AUTOSAR XML (schema 4-2-1)
# Copyright © Vector Informatik GmbH 2016
# License is invalid! Element <SLP> cannot be found.
# The created file must only be used with Vectors MICROSAR Basic Software. Please contact Vector Informatik to obtain a license.
standard types defined: boolean, sint8, uint8
package /VehicleProject
  system System
package /NM
  nm config NmConfig: can-nm-cluster-coupling=coupled-cluster=CAN00_CAN
    can nm cluster CAN00_CAN: communication-cluster=CAN00, nm-channel-id=0, nm-msg-cycle-time=0.1, nm-network-timeout=1, nm-repeat-message-time=0.4, nm-user-data-length=6, nm-wait-bus-sleep-time=0.75
      can nm node MyECU: controller=CT_CAN00, nm-if-ecu=MyECU_CAN, nm-node-id=0, rx-nm-pdu=msg_nm_RearECU_oCAN00, tx-nm-pdu=msg_nm_MyECU_oCAN00, nm-msg-cycle-offset=0, nm-msg-reduced-time=0.05, nm-range-config={lower-can-id=1024, upper-can-id=1087}
      can nm node RearECU: nm-if-ecu=RearECU_CAN, nm-node-id=1, rx-nm-pdu=msg_nm_MyECU_oCAN00, tx-nm-pdu=msg_nm_RearECU_oCAN00, nm-msg-cycle-offset=0, nm-msg-reduced-time=0.05, nm-range-config={lower-can-id=1024, upper-can-id=1087}
      can nm node Tester: nm-if-ecu=Tester_CAN, nm-node-id=0, nm-passive-mode-enabled=true, nm-msg-cycle-offset=0, nm-msg-reduced-time=0.05, nm-range-config={lower-can-id=1024, upper-can-id=1087}
    nm-if-ecus:
      nm ecu MyECU_CAN: ecu-instance=MyECU, nm-node-id-enabled=true, nm-user-data-enabled=true
      nm ecu RearECU_CAN: nm-node-id-enabled=true, nm-user-data-enabled=true
      nm ecu Tester_CAN: nm-node-id-enabled=true, nm-passive-mode-enabled=true, nm-user-data-enabled=true
package /TP
  can tp config CAN00_CAN: communication-cluster=CAN00, can-tp-ecu{cycle-time-main-function=0.005, ecu-instance=MyECU}
    can tp channel TPCH: channel-id=0, channel-mode=FULL-DUPLEX-MODE
    tp-connections:
      addressing-format=STANDARD, can-tp-channel=TPCH, data-pdu=msg_diag_RequestGlobal_Tp_oCAN00, receiver=TN_MyECU, ta-type=FUNCTIONAL, tp-sdu=msg_diag_RequestGlobal_oCAN00, transmitter=TN_Tester
      addressing-format=STANDARD, can-tp-channel=TPCH, data-pdu=msg_diag_Response_MyECU_Tp_oCAN00, flow-control-pdu=msg_diag_Request_MyECU_Tp_oCAN00, receiver=TN_Tester, ta-type=PHYSICAL, tp-sdu=msg_diag_Response_MyECU_oCAN00, transmitter=TN_MyECU
      addressing-format=STANDARD, can-tp-channel=TPCH, data-pdu=msg_diag_Request_MyECU_Tp_oCAN00, flow-control-pdu=msg_diag_Response_MyECU_Tp_oCAN00, receiver=TN_MyECU, ta-type=PHYSICAL, tp-sdu=msg_diag_Request_MyECU_oCAN00, transmitter=TN_Tester
    can tp node TN_MyECU: connector=CN_CAN00
    can tp node TN_Tester
package /Cluster
  can cluster CAN00: protocol-name=CAN
    can physical channel CHNL: comm-connectors=CN_CAN00
      frame msg_diag_Request_MyECU_oCAN00: id 0x610, to MyECU, frame-length=8, can-addressing-mode=STANDARD
        n pdu msg_diag_Request_MyECU_Tp_oCAN00: length=8
      frame msg_diag_RequestGlobal_oCAN00: id 0x614, to MyECU, frame-length=8, can-addressing-mode=STANDARD
        n pdu msg_diag_RequestGlobal_Tp_oCAN00: length=8
      frame msg_diag_Response_MyECU_oCAN00: id 0x612, from MyECU, frame-length=8, can-addressing-mode=STANDARD
        n pdu msg_diag_Response_MyECU_Tp_oCAN00: length=8
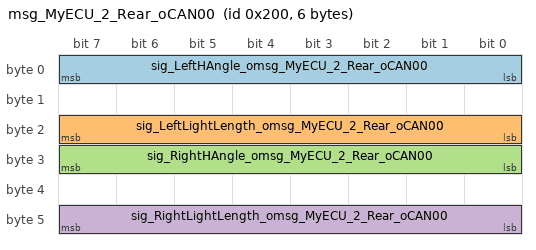
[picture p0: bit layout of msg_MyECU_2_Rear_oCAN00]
      frame msg_MyECU_2_Rear_oCAN00: id 0x200, from MyECU, frame-length=6, can-addressing-mode=STANDARD
        pdu msg_MyECU_2_Rear_oCAN00: length=6, minimum-delay=0, transmission-mode-false-timing=cyclic-timing={time-offset=0, time-period=0.1}, transmission-mode-true-timing=cyclic-timing={time-offset=0, time-period=0.1}, unused-bit-pattern=0
          signal sig_LeftHAngle_omsg_MyECU_2_Rear_oCAN00: start 0, 8 bit, little-endian, init-value=0, base-type=sint8, compu {phys=raw for raw -128..127}, transfer-property=PENDING
          signal sig_LeftLightLength_omsg_MyECU_2_Rear_oCAN00: start 16, 8 bit, little-endian, init-value=0, base-type=uint8, compu {phys=raw for raw 0..255}, transfer-property=PENDING
          signal sig_RightHAngle_omsg_MyECU_2_Rear_oCAN00: start 24, 8 bit, little-endian, init-value=0, base-type=sint8, compu {phys=raw for raw -128..127}, transfer-property=PENDING
          signal sig_RightLightLength_omsg_MyECU_2_Rear_oCAN00: start 40, 8 bit, little-endian, init-value=0, base-type=uint8, compu {phys=raw for raw 0..255}, transfer-property=PENDING
      frame msg_MyECU_2_Rear_Door_oCAN00: id 0x100, from MyECU, frame-length=8, can-addressing-mode=STANDARD
        pdu msg_MyECU_2_Rear_Door_oCAN00: length=8, minimum-delay=0, unused-bit-pattern=0
          signal sig_DoorLock_omsg_MyECU_2_Rear_Door_oCAN00: start 0, 8 bit, little-endian, init-value=0, base-type=sint8, compu {phys=raw for raw 0..1}, transfer-property=PENDING
      frame msg_nm_MyECU_oCAN00: id 0x400, from MyECU, frame-length=8, can-addressing-mode=STANDARD
        nm pdu msg_nm_MyECU_oCAN00: length=8, unused-bit-pattern=0
      frame msg_nm_RearECU_oCAN00: id 0x401, to MyECU, frame-length=8, can-addressing-mode=STANDARD
        nm pdu msg_nm_RearECU_oCAN00: length=8, unused-bit-pattern=0
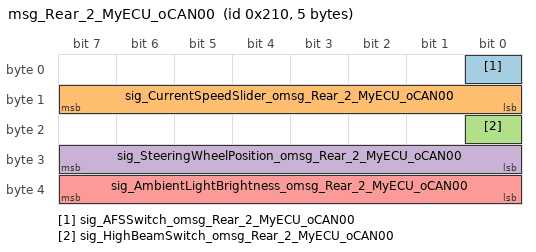
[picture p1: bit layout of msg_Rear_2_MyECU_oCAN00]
      frame msg_Rear_2_MyECU_oCAN00: id 0x210, to MyECU, frame-length=5, can-addressing-mode=STANDARD
        pdu msg_Rear_2_MyECU_oCAN00: length=5, minimum-delay=0, transmission-mode-false-timing=cyclic-timing={time-offset=0, time-period=0.1}, transmission-mode-true-timing=cyclic-timing={time-offset=0, time-period=0.1}, unused-bit-pattern=0
          signal sig_AFSSwitch_omsg_Rear_2_MyECU_oCAN00: start 0, 1 bit, little-endian, init-value=0, base-type=boolean, compu {phys=raw for raw 0..1}, transfer-property=PENDING, to MyECU
          signal sig_CurrentSpeedSlider_omsg_Rear_2_MyECU_oCAN00: start 8, 8 bit, little-endian, init-value=0, base-type=uint8, compu {phys=raw for raw 0..255}, transfer-property=PENDING, to MyECU
          signal sig_HighBeamSwitch_omsg_Rear_2_MyECU_oCAN00: start 16, 1 bit, little-endian, init-value=0, base-type=boolean, compu {phys=raw for raw 0..1}, transfer-property=PENDING, to MyECU
          signal sig_SteeringWheelPosition_omsg_Rear_2_MyECU_oCAN00: start 24, 8 bit, little-endian, init-value=0, base-type=sint8, compu {phys=raw for raw -128..127}, transfer-property=PENDING, to MyECU
          signal sig_AmbientLightBrightness_omsg_Rear_2_MyECU_oCAN00: start 32, 8 bit, little-endian, init-value=0, base-type=uint8, compu {phys=raw for raw 0..255}, transfer-property=PENDING, to MyECU
      pdu triggering PT_msg_diag_Request_MyECU: pdu=msg_diag_Request_MyECU_oCAN00, to MyECU
      pdu triggering PT_msg_diag_RequestGlobal: pdu=msg_diag_RequestGlobal_oCAN00, to MyECU
      pdu triggering PT_msg_diag_Response_MyECU: pdu=msg_diag_Response_MyECU_oCAN00, from MyECU
package /ECU
  ecu instance MyECU: associated-com-i-pdu-group=[MyECU_oCAN00_Rx, MyECU_oCAN00_Tx]
    can communication controller CT_CAN00
    can communication connector CN_CAN00: comm-controller=CT_CAN00
package /IPDUGroup
  i signal i pdu group MyECU_oCAN00_Rx: communication-direction=IN, i-signal-i-pdus=msg_Rear_2_MyECU_oCAN00
  i signal i pdu group MyECU_oCAN00_Tx: communication-direction=OUT, i-signal-i-pdus=[msg_MyECU_2_Rear_Door_oCAN00, msg_MyECU_2_Rear_oCAN00]
package /PDU
  dcm i pdu msg_diag_Request_MyECU_oCAN00: length=8, diag-pdu-type=DIAG-REQUEST
  dcm i pdu msg_diag_RequestGlobal_oCAN00: length=7, diag-pdu-type=DIAG-REQUEST
  dcm i pdu msg_diag_Response_MyECU_oCAN00: length=8, diag-pdu-type=DIAG-RESPONSE
